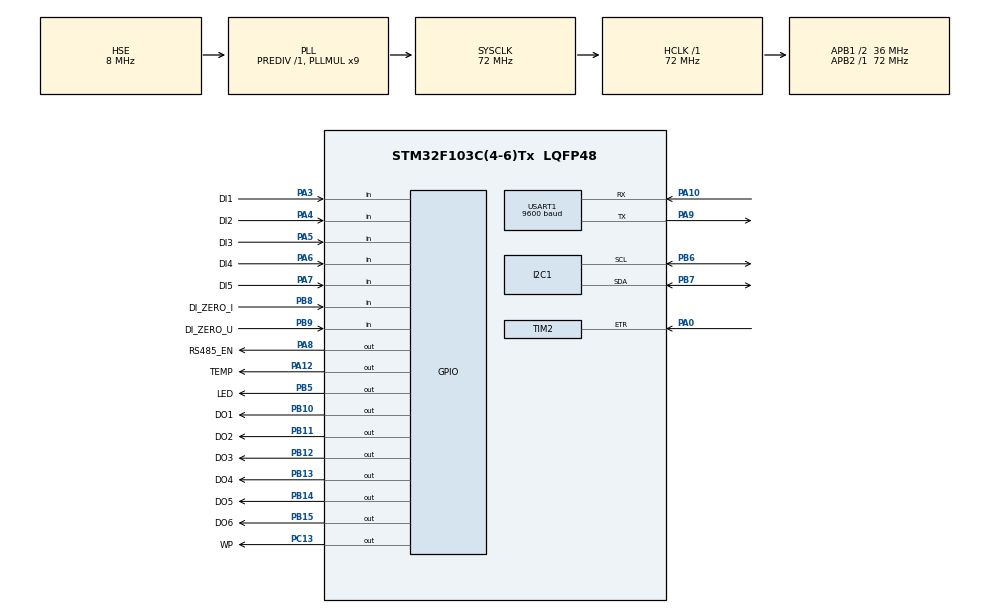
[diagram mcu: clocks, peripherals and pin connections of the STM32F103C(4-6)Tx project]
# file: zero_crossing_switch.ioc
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IWDG.Prescaler=IWDG_PRESCALER_256
Mcu.Family=STM32F1
Mcu.Name=STM32F103C(4-6)Tx
Mcu.Package=LQFP48
NVIC.PriorityGroup=NVIC_PRIORITYGROUP_4
NVIC.TIM2_IRQn=true\:1\:0\:true\:false\:true\:true\:true
NVIC.TIM3_IRQn=true\:0\:0\:false\:false\:true\:true\:true
NVIC.USART1_IRQn=true\:0\:0\:false\:false\:true\:true\:true
PA0-WKUP.Signal=S_TIM2_CH1_ETR
PA10.Mode=Asynchronous
PA10.Signal=USART1_RX
PA12.GPIO_Label=TEMP
PA12.GPIO_ModeDefaultOutputPP=GPIO_MODE_OUTPUT_OD
PA12.GPIO_Speed=GPIO_SPEED_FREQ_HIGH
PA12.PinState=GPIO_PIN_SET
PA12.Signal=GPIO_Output
PA13.Mode=Serial_Wire
PA13.Signal=SYS_JTMS-SWDIO
PA14.Mode=Serial_Wire
PA14.Signal=SYS_JTCK-SWCLK
PA3.GPIO_Label=DI1
PA3.GPIO_PuPd=GPIO_PULLUP
PA3.Signal=GPIO_Input
PA4.GPIO_Label=DI2
PA4.GPIO_PuPd=GPIO_PULLUP
PA4.Signal=GPIO_Input
PA5.GPIO_Label=DI3
PA5.GPIO_PuPd=GPIO_PULLUP
PA5.Signal=GPIO_Input
PA6.GPIO_Label=DI4
PA6.GPIO_PuPd=GPIO_PULLUP
PA6.Signal=GPIO_Input
PA7.GPIO_Label=DI5
PA7.GPIO_PuPd=GPIO_PULLUP
PA7.Signal=GPIO_Input
PA8.GPIO_Label=RS485_EN
PA8.Signal=GPIO_Output
PA9.Mode=Asynchronous
PA9.Signal=USART1_TX
PB10.GPIO_Label=DO1
PB10.GPIO_Speed=GPIO_SPEED_FREQ_HIGH
PB10.Signal=GPIO_Output
PB11.GPIO_Label=DO2
PB11.GPIO_Speed=GPIO_SPEED_FREQ_HIGH
PB11.Signal=GPIO_Output
PB12.GPIO_Label=DO3
PB12.GPIO_Speed=GPIO_SPEED_FREQ_HIGH
PB12.Signal=GPIO_Output
PB13.GPIO_Label=DO4
PB13.GPIO_Speed=GPIO_SPEED_FREQ_HIGH
PB13.Signal=GPIO_Output
PB14.GPIO_Label=DO5
PB14.GPIO_Speed=GPIO_SPEED_FREQ_HIGH
PB14.Signal=GPIO_Output
PB15.GPIO_Label=DO6
PB15.GPIO_Speed=GPIO_SPEED_FREQ_HIGH
PB15.Signal=GPIO_Output
PB5.GPIO_Label=LED
PB5.PinState=GPIO_PIN_SET
PB5.Signal=GPIO_Output
PB6.Mode=I2C
PB6.Signal=I2C1_SCL
PB7.Mode=I2C
PB7.Signal=I2C1_SDA
PB8.GPIO_Label=DI_ZERO_I
PB8.GPIO_PuPd=GPIO_PULLUP
PB8.Signal=GPIO_Input
PB9.GPIO_Label=DI_ZERO_U
PB9.GPIO_PuPd=GPIO_PULLUP
PB9.Signal=GPIO_Input
PC13-TAMPER-RTC.GPIO_Label=WP
PC13-TAMPER-RTC.PinState=GPIO_PIN_SET
PC13-TAMPER-RTC.Signal=GPIO_Output
PD0-OSC_IN.Mode=HSE-External-Oscillator
PD0-OSC_IN.Signal=RCC_OSC_IN
PD1-OSC_OUT.Mode=HSE-External-Oscillator
PD1-OSC_OUT.Signal=RCC_OSC_OUT
ProjectManager.HeapSize=0x200
ProjectManager.StackSize=0x400
ProjectManager.TargetToolchain=MDK-ARM V5.27
RCC.AHBFreq_Value=72000000
RCC.APB1CLKDivider=RCC_HCLK_DIV2
RCC.APB1Freq_Value=36000000
RCC.APB1TimFreq_Value=72000000
RCC.APB2Freq_Value=72000000
RCC.APB2TimFreq_Value=72000000
RCC.HCLKFreq_Value=72000000
RCC.PLLMUL=RCC_PLL_MUL9
RCC.PLLSourceVirtual=RCC_PLLSOURCE_HSE
RCC.SYSCLKFreq_VALUE=72000000
RCC.SYSCLKSource=RCC_SYSCLKSOURCE_PLLCLK
RCC.USBFreq_Value=72000000
SH.S_TIM2_CH1_ETR.0=TIM2_ETR,ClockSourceETR_Mode2
TIM2.AutoReloadPreload=TIM_AUTORELOAD_PRELOAD_ENABLE
TIM2.Period=0xFFFF
TIM2.Prescaler=0
TIM3.AutoReloadPreload=TIM_AUTORELOAD_PRELOAD_ENABLE
TIM3.Period=9
TIM3.Prescaler=7199
USART1.BaudRate=9600
USART1.VirtualMode=VM_ASYNC
VP_IWDG_VS_IWDG.Mode=IWDG_Activate
VP_TIM3_VS_ClockSourceINT.Mode=Internal
board=custom

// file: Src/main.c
/* USER CODE BEGIN Header */
/**
  ******************************************************************************
  * @file           : main.c
  * @brief          : Main program body
  ******************************************************************************
  * @attention
  *
  * <h2><center>&copy; Copyright (c) 2020 STMicroelectronics.
  * All rights reserved.</center></h2>
  *
  * This software component is licensed by ST under BSD 3-Clause license,
  * the "License"; You may not use this file except in compliance with the
  * License. You may obtain a copy of the License at:
  *                        opensource.org/licenses/BSD-3-Clause
  *
  ******************************************************************************
  */
/* USER CODE END Header */

#include "main.h"
#include "i2c.h"
#include "iwdg.h"
#include "tim.h"
#include "usart.h"
#include "gpio.h"

/* USER CODE BEGIN Includes */
#include "task.h"
#include "switch.h"
#include "modbus_interface.h"
/* USER CODE END Includes */

void SystemClock_Config(void);

/* USER CODE BEGIN 0 */
extern SwitchTypeDef sw;
/* USER CODE END 0 */

int main(void)
{

  /* MCU Configuration--------------------------------------------------------*/

  /* Reset of all peripherals, Initializes the Flash interface and the Systick. */
  HAL_Init();

  /* Configure the system clock */
  SystemClock_Config();

  /* Initialize all configured peripherals */
  MX_GPIO_Init();
  MX_IWDG_Init();
  MX_I2C1_Init();
  MX_TIM2_Init();
  MX_TIM3_Init();
  MX_USART1_UART_Init();
  /* USER CODE BEGIN 2 */
  Switch_Init();  //参数初始化在定时器启动前
  HAL_TIM_Base_Start_IT(&htim2);
  HAL_TIM_Base_Start_IT(&htim3);
  Switch_Goto_Pre();  //开关去预置位，需要读遥信，所以要在定时器启动后
  Modbus_Interface_Init(&sw);
  /* USER CODE END 2 */

  /* Infinite loop */
  /* USER CODE BEGIN WHILE */
  while (1)
  {
    Task_Main();
    /* USER CODE END WHILE */

  }
}

void SystemClock_Config(void)
{
  RCC_OscInitTypeDef RCC_OscInitStruct = {0};
  RCC_ClkInitTypeDef RCC_ClkInitStruct = {0};

  /** Initializes the CPU, AHB and APB busses clocks
  */
  RCC_OscInitStruct.OscillatorType = RCC_OSCILLATORTYPE_LSI|RCC_OSCILLATORTYPE_HSE;
  RCC_OscInitStruct.HSEState = RCC_HSE_ON;
  RCC_OscInitStruct.HSEPredivValue = RCC_HSE_PREDIV_DIV1;
  RCC_OscInitStruct.HSIState = RCC_HSI_ON;
  RCC_OscInitStruct.LSIState = RCC_LSI_ON;
  RCC_OscInitStruct.PLL.PLLState = RCC_PLL_ON;
  RCC_OscInitStruct.PLL.PLLSource = RCC_PLLSOURCE_HSE;
  RCC_OscInitStruct.PLL.PLLMUL = RCC_PLL_MUL9;
  if (HAL_RCC_OscConfig(&RCC_OscInitStruct) != HAL_OK)
  {
    Error_Handler();
  }
  /** Initializes the CPU, AHB and APB busses clocks
  */
  RCC_ClkInitStruct.ClockType = RCC_CLOCKTYPE_HCLK|RCC_CLOCKTYPE_SYSCLK
                              |RCC_CLOCKTYPE_PCLK1|RCC_CLOCKTYPE_PCLK2;
  RCC_ClkInitStruct.SYSCLKSource = RCC_SYSCLKSOURCE_PLLCLK;
  RCC_ClkInitStruct.AHBCLKDivider = RCC_SYSCLK_DIV1;
  RCC_ClkInitStruct.APB1CLKDivider = RCC_HCLK_DIV2;
  RCC_ClkInitStruct.APB2CLKDivider = RCC_HCLK_DIV1;

  if (HAL_RCC_ClockConfig(&RCC_ClkInitStruct, FLASH_LATENCY_2) != HAL_OK)
  {
    Error_Handler();
  }
}

void Error_Handler(void)
{
}

/************************ (C) COPYRIGHT STMicroelectronics *****END OF FILE****/
